# R7FA6E10F register map
Vendor: Renesas Electronics Corporation; Series: RA6; File version: 1.20.00
CPU: CM33 r0p4, little endian, MPU, FPU, VTOR, 4 interrupt priority bits, 96 interrupts
Registers are 8-bit, read-write, reset 0x0 unless marked. A register's access mark holds for its fields unless they carry their own. Offsets are from the block's base; [hi:lo] are bit positions; {n}, {i} and the like mark numbered series; 'fields as' and 'values as' point back to an identical list.

## USBFS — USB 2.0 Full-Speed Module
Base 0x40090000
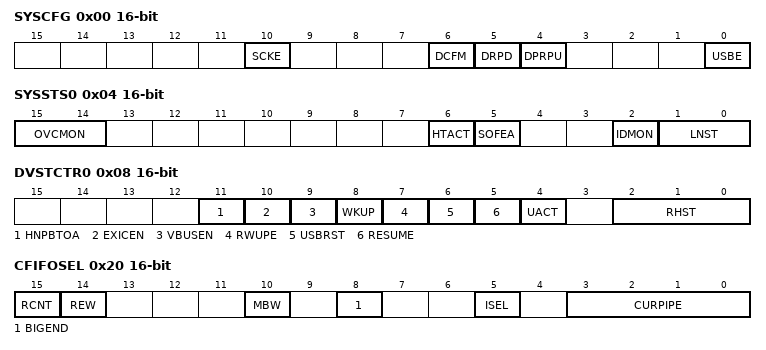
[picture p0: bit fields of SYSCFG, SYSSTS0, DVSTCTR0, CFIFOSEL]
0x00 SYSCFG 16-bit — System Configuration Control Register
  [10] SCKE — USB Clock Enable
    0=Stop clock supply to the USBFS; 1=Enable clock supply to the USBFS
  [6] DCFM — Controller Function Select
    0=Select device controller; 1=Select host controller
  [5] DRPD — D+/D– Line Resistor Control
    0=Disable line pull-down; 1=Enable line pull-down
  [4] DPRPU — D+ Line Resistor Control
    0=Disable line pull-up; 1=Enable line pull-up
  [0] USBE — USBFS Operation Enable
    0=Disable; 1=Enable
0x04 SYSSTS0 16-bit ro (reset mask 0x3FFB) — System Configuration Status Register 0
  [15:14] OVCMON — External USB_OVRCURA/ USB_OVRCURB Input Pin Monitor
  [6] HTACT — USB Host Sequencer Status Monitor
    0=Host sequencer completely stopped; 1=Host sequencer not completely stopped
  [5] SOFEA — Active Monitor When the Host Controller Is Selected
    0=SOF output stopped; 1=SOF output operating
  [2] IDMON — External ID0 Input Pin Monitor
    0=USB_ID pin is low; 1=USB_ID pin is high
  [1:0] LNST — USB Data Line Status Monitor
0x08 DVSTCTR0 16-bit — Device State Control Register 0
  [11] HNPBTOA — Host Negotiation Protocol (HNP) Control
  [10] EXICEN — USB_EXICEN Output Pin Control
    0=Output low on external USB_EXICEN pin; 1=Output high on external USB_EXICEN pin
  [9] VBUSEN — USB_VBUSEN Output Pin Control
    0=Output low on external USB_VBUSEN pin; 1=Output high on external USB_VBUSEN pin
  [8] WKUP — Wakeup Output
    0=Do not output remote wakeup signal; 1=Output remote wakeup signal
  [7] RWUPE — Wakeup Detection Enable
    0=Disable downstream port remote wakeup; 1=Enable downstream port remote wakeup
  [6] USBRST — USB Bus Reset Output
    0=Do not output USB bus reset signal; 1=Output USB bus reset signal
  [5] RESUME — Resume Output
    0=Do not output resume signal; 1=Output resume signal
  [4] UACT — USB Bus Enable
    0=Disable downstream port (disable SOF transmission); 1=Enable downstream port (enable SOF transmission)
  [2:0] RHST ro — USB Bus Reset Status
    0=In host controller mode: Communication speed indeterminate (powered state or no connection) In device controller mode: Communication speed indeterminate; 1=In host controller mode: Low-speed connection In device controller mode: USB bus reset in progress; 2=In host controller mode: Full-speed connection In device controller mode: USB bus reset in progress or full-speed connection; 3=Setting prohibited; other=Others (In host controller mode: USB bus reset in progress In device controller mode: Setting prohibited)
0x14 CFIFO 16-bit — CFIFO Port Register
  [15:0] FIFOPORT
0x14 CFIFOL (alternate view of CFIFO) — CFIFO Port Register
  [7:0] FIFOPORT
{0x18+4i} D{i}FIFO (i=0..1) 16-bit — D{i}FIFO Port Register
  [15:0] FIFOPORT
{0x18+4i} D{i}FIFOL (i=0..1) (alternate view of D{i}FIFO) — D{i}FIFO Port Register
  [7:0] FIFOPORT
0x20 CFIFOSEL 16-bit — CFIFO Port Select Register
  [15] RCNT — Read Count Mode
    0=The DTLN[8:0] bits (CFIFOCTR.DTLN[8:0], D0FIFOCTR.DTLN[8:0], D1FIFOCTR.DTLN[8:0]) are cleared when all receive data is read from the CFIFO. In double buffer mode, the DTLN[8:0] value is cleared when all data is read from only a single plane.; 1=The DTLN[8:0] bits are decremented each time the receive data is read from the CFIFO
  [14] REW wo — Buffer Pointer Rewind
    0=Do not rewind buffer pointer; 1=Rewind buffer pointer
  [10] MBW — CFIFO Port Access Bit Width
    0=8-bit width; 1=16-bit width
  [8] BIGEND — CFIFO Port Endian Control
    0=Little endian; 1=Big endian
  [5] ISEL — CFIFO Port Access Direction When DCP Is Selected
    0=Select reading from the FIFO buffer; 1=Select writing to the FIFO buffer
  [3:0] CURPIPE — CFIFO Port Access Pipe Specification
    0=Default Control Pipe; {v}=Pipe {v} (v=1..9); other=Others (Setting prohibited)
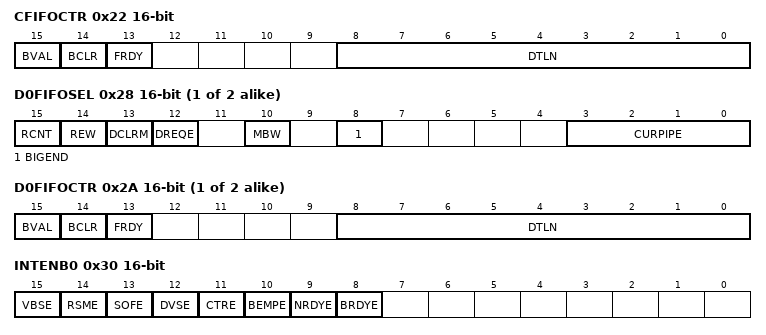
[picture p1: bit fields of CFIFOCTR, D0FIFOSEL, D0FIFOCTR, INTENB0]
0x22 CFIFOCTR 16-bit — CFIFO Port Control Register
  [15] BVAL — Buffer Memory Valid Flag
    0=Invalid (writing 0 has no effect); 1=Writing ended
  [14] BCLR wo — CPU Buffer Clear
    0=No operation; 1=Clear FIFO buffer on the CPU side
  [13] FRDY ro — FIFO Port Ready
    0=FIFO port access disabled; 1=FIFO port access enabled
  [8:0] DTLN ro — Receive Data Length
{0x28+4i} D{i}FIFOSEL (i=0..1) 16-bit — D{i}FIFO Port Select Register
  [15] RCNT — Read Count Mode
    0=Clear DTLN[8:0] bits in (CFIFOCTR.DTLN[8:0], D0FIFOCTR.DTLN[8:0], D1FIFOCTR.DTLN[8:0]) when all receive data is read from DnFIFO (after read of a single plane in double buffer mode); 1=Decrement DTLN[8:0] bits each time receive data is read from DnFIFO
  [14] REW wo — Buffer Pointer Rewind
    0=Do not rewind buffer pointer; 1=Rewind buffer pointer
  [13] DCLRM — Auto Buffer Memory Clear Mode Accessed after Specified Pipe Data is Read
    0=Disable auto buffer clear mode; 1=Enable auto buffer clear mode
  [12] DREQE — DMA/DTC Transfer Request Enable
    0=Disable DMA/DTC transfer request; 1=Enable DMA/DTC transfer request
  [10] MBW — FIFO Port Access Bit Width
    0=8-bit width; 1=16-bit width
  [8] BIGEND — FIFO Port Endian Control
    0=Little endian; 1=Big endian
  [3:0] CURPIPE — FIFO Port Access Pipe Specification
    values as CFIFOSEL.CURPIPE
{0x2A+4i} D{i}FIFOCTR (i=0..1) 16-bit — D{i}FIFO Port Control Register
  [15] BVAL — Buffer Memory Valid Flag
    0=Invalid (writing 0 has no effect); 1=Writing ended
  [14] BCLR — CPU Buffer Clear
    0=No operation; 1=Clear FIFO buffer on the CPU side
  [13] FRDY ro — FIFO Port Ready
    0=FIFO port access disabled; 1=FIFO port access enabled
  [8:0] DTLN ro — Receive Data Length
0x30 INTENB0 16-bit — Interrupt Enable Register 0
  [all] fields
    0=Disable interrupt request; 1=Enable interrupt request
  [15] VBSE — VBUS Interrupt Enable
  [14] RSME — Resume Interrupt Enable
  [13] SOFE — Frame Number Update Interrupt Enable
  [12] DVSE — Device State Transition Interrupt Enable
  [11] CTRE — Control Transfer Stage Transition Interrupt Enable
  [10] BEMPE — Buffer Empty Interrupt Enable
  [9] NRDYE — Buffer Not Ready Response Interrupt Enable
  [8] BRDYE — Buffer Ready Interrupt Enable
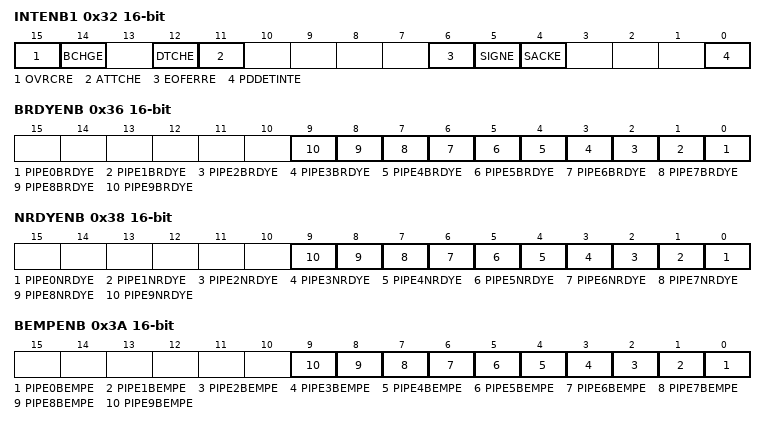
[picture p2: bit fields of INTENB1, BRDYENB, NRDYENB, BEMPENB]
0x32 INTENB1 16-bit — Interrupt Enable Register 1
  [all] fields
    0=Disable interrupt request; 1=Enable interrupt request
  [15] OVRCRE — Overcurrent Input Change Interrupt Enable
  [14] BCHGE — USB Bus Change Interrupt Enable
  [12] DTCHE — Disconnection Detection Interrupt Enable
  [11] ATTCHE — Connection Detection Interrupt Enable
  [6] EOFERRE — EOF Error Detection Interrupt Enable
  [5] SIGNE — Setup Transaction Error Interrupt Enable
  [4] SACKE — Setup Transaction Normal Response Interrupt Enable
  [0] PDDETINTE — PDDETINT Detection Interrupt Request Enable
0x36 BRDYENB 16-bit — BRDY Interrupt Enable Register
  [all] fields
    0=Disable interrupt request; 1=Enable interrupt request
  [n] PIPE{n}BRDYE (n=0..9) — BRDY Interrupt Enable for Pipe {n}
0x38 NRDYENB 16-bit — NRDY Interrupt Enable Register
  [all] fields
    0=Disable interrupt request; 1=Enable interrupt request
  [n] PIPE{n}NRDYE (n=0..9) — NRDY Interrupt Enable for Pipe {n}
0x3A BEMPENB 16-bit — BEMP Interrupt Enable Register
  [all] fields
    0=Disable interrupt request; 1=Enable interrupt request
  [n] PIPE{n}BEMPE (n=0..9) — BEMP Interrupt Enable for Pipe {n}
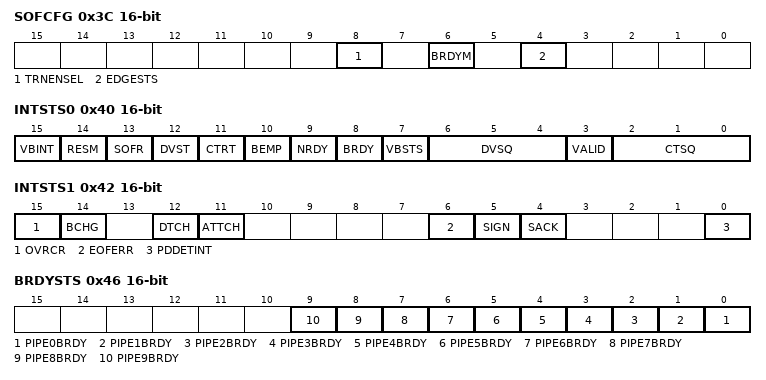
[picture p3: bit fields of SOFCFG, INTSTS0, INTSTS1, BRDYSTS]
0x3C SOFCFG 16-bit — SOF Output Configuration Register
  [8] TRNENSEL — Transaction-Enabled Time Select
    0=Not low-speed communication; 1=Low-speed communication
  [6] BRDYM — BRDY Interrupt Status Clear Timing
    0=Clear BRDY flag by software; 1=Clear BRDY flag by the USBFS through a data read from the FIFO buffer or data write to the FIFO buffer
  [4] EDGESTS ro — Edge Interrupt Output Status Monitor
0x40 INTSTS0 16-bit (reset mask 0xEF6F) — Interrupt Status Register 0
  [15] VBINT — VBUS Interrupt Status
    0=No VBUS interrupt occurred; 1=VBUS interrupt occurred
  [14] RESM — Resume Interrupt Status
    0=No resume interrupt occurred; 1=Resume interrupt occurred
  [13] SOFR — Frame Number Refresh Interrupt Status
    0=No SOF interrupt occurred; 1=SOF interrupt occurred
  [12] DVST — Device State Transition Interrupt Status
    0=No device state transition interrupt occurred; 1=Device state transition interrupt occurred
  [11] CTRT — Control Transfer Stage Transition Interrupt Status
    0=No control transfer stage transition interrupt occurred; 1=Control transfer stage transition interrupt occurred
  [10] BEMP ro — Buffer Empty Interrupt Status
    0=No BEMP interrupt occurred; 1=BEMP interrupt occurred
  [9] NRDY ro — Buffer Not Ready Interrupt Status
    0=No NRDY interrupt occurred; 1=NRDY interrupt occurred
  [8] BRDY ro — Buffer Ready Interrupt Status
    0=No BRDY interrupt occurred; 1=BRDY interrupt occurred
  [7] VBSTS ro — VBUS Input Status
    0=USB_VBUS pin is low; 1=USB_VBUS pin is high
  [6:4] DVSQ ro — Device State
    0=Powered state; 1=Default state; 2=Address state; 3=Configured state; other=Others (Suspend state)
  [3] VALID — USB Request Reception
    0=Setup packet not received; 1=Setup packet received
  [2:0] CTSQ ro — Control Transfer Stage
    0=Idle or setup stage; 1=Control read data stage; 2=Control read status stage; 3=Control write data stage; 4=Control write status stage; 5=Control write (no data) status stage; 6=Control transfer sequence error
0x42 INTSTS1 16-bit — Interrupt Status Register 1
  [15] OVRCR — Overcurrent Input Change Interrupt Status
    0=No OVRCR interrupt occurred; 1=OVRCR interrupt occurred
  [14] BCHG — USB Bus Change Interrupt Status
    0=No BCHG interrupt occurred; 1=BCHG interrupt occurred
  [12] DTCH — USB Disconnection Detection Interrupt Status
    0=No DTCH interrupt occurred; 1=DTCH interrupt occurred
  [11] ATTCH — ATTCH Interrupt Status
    0=No ATTCH interrupt occurred; 1=ATTCH interrupt occurred
  [6] EOFERR — EOF Error Detection Interrupt Status
    0=No EOFERR interrupt occurred; 1=EOFERR interrupt occurred
  [5] SIGN — Setup Transaction Error Interrupt Status
    0=No SIGN interrupt occurred; 1=SIGN interrupt occurred
  [4] SACK — Setup Transaction Normal Response Interrupt Status
    0=No SACK interrupt occurred; 1=SACK interrupt occurred
  [0] PDDETINT — PDDET Detection Interrupt Status Flag
    0=No PDDET interrupt occurred; 1=PDDET interrupt occurred
0x46 BRDYSTS 16-bit — BRDY Interrupt Status Register
  [all] fields
    0=No BRDY interrupt occurred; 1=BRDY interrupt occurred
  [n] PIPE{n}BRDY (n=0..9) — BRDY Interrupt Status for Pipe {n}
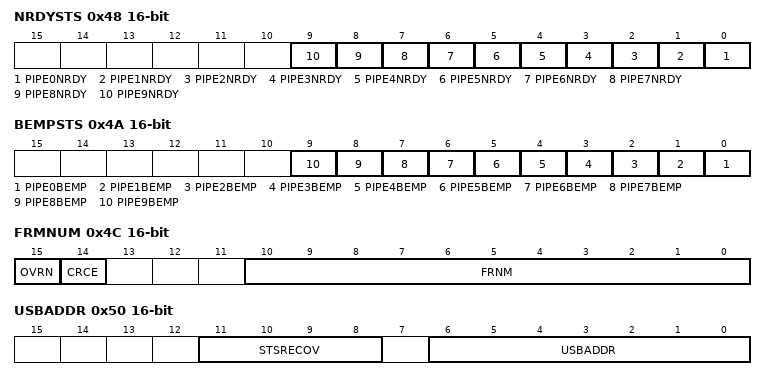
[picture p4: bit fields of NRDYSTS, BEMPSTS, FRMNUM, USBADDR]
0x48 NRDYSTS 16-bit — NRDY Interrupt Status Register
  [all] fields
    0=No NRDY interrupt occurred; 1=NRDY interrupt occurred
  [n] PIPE{n}NRDY (n=0..9) — NRDY Interrupt Status for Pipe {n}
0x4A BEMPSTS 16-bit — BEMP Interrupt Status Register
  [all] fields
    0=No BEMP interrupt occurred; 1=BEMP interrupt occurred
  [n] PIPE{n}BEMP (n=0..9) — BEMP Interrupt Status for Pipe {n}
0x4C FRMNUM 16-bit — Frame Number Register
  [15] OVRN — Overrun/Underrun Detection Status
    0=No error occurred; 1=Error occurred
  [14] CRCE — Receive Data Error
    0=No error occurred; 1=Error occurred
  [10:0] FRNM ro — Frame Number
0x4E DVCHGR 16-bit — Device State Change Register
  [15] DVCHG — Device State Change
    0=Disable writes to the USBADDR.STSRECOV[3:0] and USBADDR.USBADDR[6:0] bits; 1=Enable writes to the USBADDR.STSRECOV[3:0] and USBADDR.USBADDR[6:0] bits
0x50 USBADDR 16-bit — USB Address Register
  [11:8] STSRECOV — Status Recovery
    4=Recovery in device controller mode: Setting prohibited Recovery in host controller mode: Return to the low-speed state (bits DVSTCTR0.RHST[2:0] = 001b); 8=Recovery in device controller mode: Setting prohibited Recovery in host controller mode: Return to the full-speed state (bits DVSTCTR0.RHST[2:0] = 010b); 9=Recovery in device controller mode: Return to the full-speed state (bits DVSTCTR0.RHST[2:0] = 010b), bits INTSTS0.DVSQ[2:0] = 001b (default state) Recovery in host controller mode: Setting prohibited; 10=Recovery in device controller mode: Return to the full-speed state (bits DVSTCTR0.RHST[2:0] = 010b), bits INTSTS0.DVSQ[2:0] = 010b (address state) Recovery in host controller mode: Setting prohibited; 11=Recovery in device controller mode: Return to the full-speed state (bits DVSTCTR0.RHST[2:0] = 010b), bits INTSTS0.DVSQ[2:0] = 011b (configured state) Recovery in host controller mode: Setting prohibited; other=Others (Setting prohibited)
  [6:0] USBADDR — USB Address
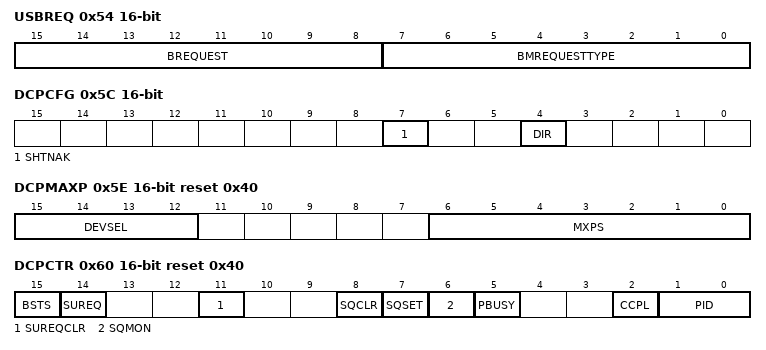
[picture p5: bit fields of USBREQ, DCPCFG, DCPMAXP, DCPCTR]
0x54 USBREQ 16-bit — USB Request Type Register
  [15:8] BREQUEST — Request
  [7:0] BMREQUESTTYPE — Request Type
0x56 USBVAL 16-bit — USB Request Value Register
  [15:0] WVALUE — Value
0x58 USBINDX 16-bit — USB Request Index Register
  [15:0] WINDEX — Index
0x5A USBLENG 16-bit — USB Request Length Register
  [15:0] WLENTUH — Length
0x5C DCPCFG 16-bit — DCP Configuration Register
  [7] SHTNAK — Pipe Disabled at End of Transfer
    0=Keep pipe open after transfer ends; 1=Disable pipe after transfer ends
  [4] DIR — Transfer Direction
    0=Data receiving direction; 1=Data transmitting direction
0x5E DCPMAXP 16-bit reset 0x40 — DCP Maximum Packet Size Register
  [15:12] DEVSEL — Device Select
    0=Address 0000b; 1=Address 0001b; 2=Address 0010b; 3=Address 0011b; 4=Address 0100b; 5=Address 0101b; other=Others (Setting prohibited)
  [6:0] MXPS — Maximum Packet Size
0x60 DCPCTR 16-bit reset 0x40 — DCP Control Register
  [15] BSTS ro — Buffer Status
    0=Buffer access disabled; 1=Buffer access enabled
  [14] SUREQ — Setup Token Transmission
    0=Invalid (writing 0 has no effect); 1=Transmit setup packet
  [11] SUREQCLR — SUREQ Bit Clear
    0=Invalid (writing 0 has no effect); 1=Clear SUREQ to 0
  [8] SQCLR — Sequence Toggle Bit Clear
    0=Invalid (writing 0 has no effect); 1=Clear the expected value for the next transaction to DATA0
  [7] SQSET — Sequence Toggle Bit Set
    0=Invalid (writing 0 has no effect); 1=Set the expected value for the next transaction to DATA1
  [6] SQMON ro — Sequence Toggle Bit Monitor
    0=DATA0; 1=ATA1
  [5] PBUSY ro — Pipe Busy
    0=DCP not used for the USB bus; 1=DCP in use for the USB bus
  [2] CCPL — Control Transfer End Enable
    0=Disable control transfer completion; 1=Enable control transfer completion
  [1:0] PID — Response PID
    0=NAK response; 1=BUF response (depends on the buffer state); 2=STALL response; 3=STALL response
0x64 PIPESEL 16-bit — Pipe Window Select Register
  [3:0] PIPESEL — Pipe Window Select
    0=No pipe selected; {v}=Pipe {v} (v=1..9); other=Others (Setting prohibited)
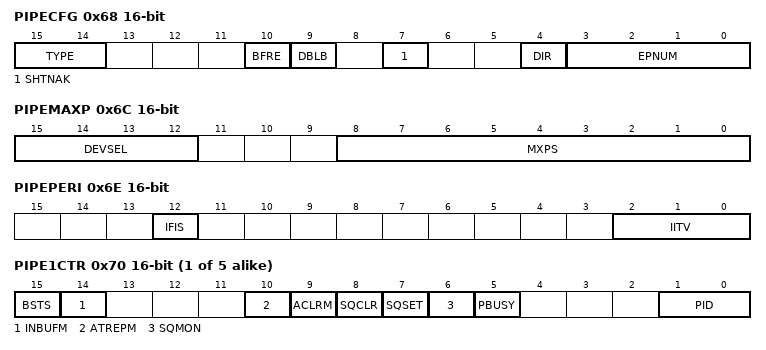
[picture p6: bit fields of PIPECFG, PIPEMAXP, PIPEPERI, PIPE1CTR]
0x68 PIPECFG 16-bit — Pipe Configuration Register
  [15:14] TYPE — Transfer Type
    0=Pipe not used; 1=Pipes 1 and 2: Bulk transfer Pipes 3 to 5: Bulk transfer Pipes 6 to 9: Setting prohibited; 2=Pipes 1 and 2: Setting prohibited Pipes 3 to 5: Setting prohibited Pipes 6 to 9: Interrupt transfer; 3=Pipes 1 and 2: Isochronous transfer Pipes 3 to 5: Setting prohibited Pipes 6 to 9: Setting prohibited
  [10] BFRE — BRDY Interrupt Operation Specification
    0=Generate BRDY interrupt on transmitting or receiving data; 1=Generate BRDY interrupt on completion of reading data
  [9] DBLB — Double Buffer Mode
    0=Single buffer; 1=Double buffer
  [7] SHTNAK — Pipe Disabled at End of Transfer
    0=Continue pipe operation after transfer ends; 1=Disable pipe after transfer ends
  [4] DIR — Transfer Direction
    0=Receiving direction; 1=Transmitting direction
  [3:0] EPNUM — Endpoint Number
0x6C PIPEMAXP 16-bit (reset mask 0xFFBF) — Pipe Maximum Packet Size Register
  [15:12] DEVSEL — Device Select
    values as DCPMAXP.DEVSEL
  [8:0] MXPS — Maximum Packet Size
0x6E PIPEPERI 16-bit — Pipe Cycle Control Register
  [12] IFIS — Isochronous IN Buffer Flush
    0=Do not flush buffer; 1=Flush buffer
  [2:0] IITV — Interval Error Detection Interval
{0x6E+2i} PIPE{i}CTR (i=1..5) 16-bit — PIPE{i} Control Registers
  [15] BSTS ro — Buffer Status
    0=Buffer access by the CPU disabled; 1=Buffer access by the CPU enabled
  [14] INBUFM ro — Transmit Buffer Monitor
    0=No data to be transmitted is in the FIFO buffer; 1=Data to be transmitted is in the FIFO buffer
  [10] ATREPM — Auto Response Mode
    0=Disable auto response mode; 1=Enable auto response mode
  [9] ACLRM — Auto Buffer Clear Mode
    0=Disable; 1=Enable (initialize all buffers)
  [8] SQCLR — Sequence Toggle Bit Clear
    values as DCPCTR.SQCLR
  [7] SQSET — Sequence Toggle Bit Set
    values as DCPCTR.SQSET
  [6] SQMON ro — Sequence Toggle Bit Confirmation
    0=DATA0; 1=DATA1
  [5] PBUSY ro — Pipe Busy
    0=Pipe n not in use for the transaction; 1=Pipe n in use for the transaction
  [1:0] PID — Response PID
    0=NAK response; 1=BUF response (depends buffer state); 2=STALL response; 3=STALL response
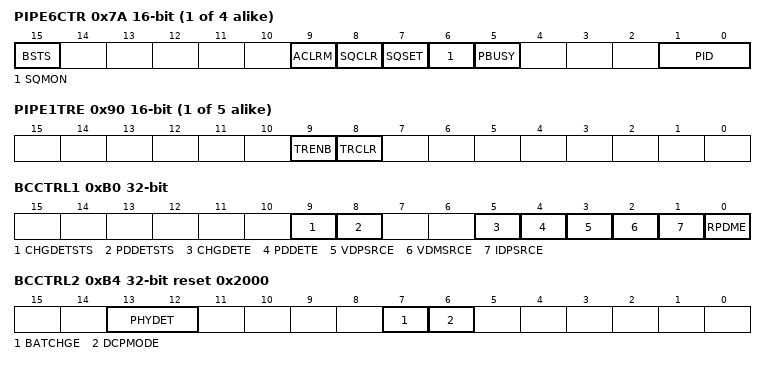
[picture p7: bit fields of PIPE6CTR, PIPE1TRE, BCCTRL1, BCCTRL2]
{0x6E+2i} PIPE{i}CTR (i=6..9) 16-bit — PIPE{i} Control Registers
  [15] BSTS ro — Buffer Status
    0=Buffer access disabled; 1=Buffer access enabled
  [9] ACLRM — Auto Buffer Clear Mode
    0=Disable; 1=Enable (all buffers initialized)
  [8] SQCLR wo — Sequence Toggle Bit Clear
    values as DCPCTR.SQCLR
  [7] SQSET wo — Sequence Toggle Bit Set
    0=Invalid (writing 0 has no effect); 1=Set the expected value for the next transaction to DATA0
  [6] SQMON ro — Sequence Toggle Bit Confirmation
    0=DATA0; 1=DATA1
  [5] PBUSY ro — Pipe Busy
    values as PIPE1CTR.PBUSY
  [1:0] PID — Response PID
    values as PIPE1CTR.PID
{0x8C+4i} PIPE{i}TRE (i=1..5) 16-bit — PIPE{i} Transaction Counter Enable Register
  [9] TRENB — Transaction Counter Enable
    0=Disable transaction counter; 1=Enable transaction counter
  [8] TRCLR — Transaction Counter Clear
    0=Invalid (writing 0 has no effect); 1=Clear counter value
{0x8E+4i} PIPE{i}TRN (i=1..5) 16-bit — PIPE{i} Transaction Counter Register
  [15:0] TRNCNT — Transaction Counter
0xB0 BCCTRL1 32-bit — Battery Charging Control Register 1
  [9] CHGDETSTS ro — D- Line 0.6 V Input Detection Status Flag
    0=Not detected; 1=Detected
  [8] PDDETSTS ro — D+ Line 0.6 V Input Detection Status Flag
    0=Not detected; 1=Detected
  [5] CHGDETE — D- Line 0.6 V Input Detection Control
    0=Disable detection; 1=Enable detection
  [4] PDDETE — D+ Line 0.6 V Input Detection Control
    0=Disable detection; 1=Enable detection
  [3] VDPSRCE — D+ Line VDPSRC (0.6 V) Output Control
    0=Stopped; 1=0.6 V output
  [2] VDMSRCE — D- Line VDMSRC (0.6 V) Output Control
    0=Stopped; 1=0.6 V output
  [1] IDPSRCE — D+ Line IDPSRC Output Control
    0=Stopped; 1=10 µA output
  [0] RPDME — D- Line Pull-down Control
    0=Disable D- Line Pull-down; 1=Enable D- Line Pull-down
0xB4 BCCTRL2 32-bit reset 0x2000 — Battery Charging Control Register 2
  [13:12] PHYDET — Detect Sensitivity Adjustment
  [7] BATCHGE — Battery Charging Enable
    0=Disable Battery Charging; 1=Enable Battery Charging
  [6] DCPMODE — Dedicated Charging Port (DCP) Mode Control
    0=Disable DCP; 1=Enable DCP
{0xD0+2i} DEVADD{i} (i=0..5) 16-bit — Device Address {i} Configuration Register
  [7:6] USBSPD — Transfer Speed of Communication Target Device
    0=Do not use DEVADDn; 1=Low-speed; 2=Full-speed; 3=Setting prohibited
0xF4 PHYSECTRL 32-bit — PHY Single-ended Receiver Control Register
  [4] CNEN — Single-ended Receiver Enable
    0=Single-ended receiver operation is disabled; 1=Single-ended receiver operation is enabled
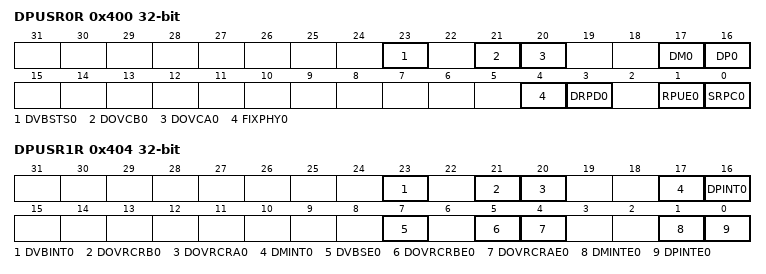
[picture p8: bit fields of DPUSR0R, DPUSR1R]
0x400 DPUSR0R 32-bit (reset mask 0xFF4CFFFF) — Deep Software Standby USB Transceiver Control/Pin Monitor Register
  [23] DVBSTS0 ro — USB VBUS Input
  [21] DOVCB0 ro — USB OVRCURB Input
  [20] DOVCA0 ro — USB OVRCURA Input
  [17] DM0 ro — USB D- Input
  [16] DP0 ro — USB D+ Input
  [4] FIXPHY0 — USB Transceiver Output Fix
    0=Fix outputs in Normal mode and on return from Deep Software Standby mode; 1=Fix outputs on transition to Deep Software Standby mode
  [3] DRPD0 — D+/D- Pull-Down Resistor Control
    0=Disable DP/DM pull-down resistor; 1=Enable DP/DM pull-down resistor
  [1] RPUE0 — DP Pull-Up Resistor Control
    0=Disable DP pull-up resistor; 1=Enable DP pull-up resistor
  [0] SRPC0 — USB Single-ended Receiver Control
    0=Disable input through DP and DM inputs; 1=Enable input through DP and DM inputs
0x404 DPUSR1R 32-bit — Deep Software Standby USB Suspend/Resume Interrupt Register
  [23] DVBINT0 ro — USB VBUS Interrupt Source Recovery
    0=System has not recovered from Deep Software Standby mode; 1=System recovered from Deep Software Standby mode because of VBUS input
  [21] DOVRCRB0 ro — USB OVRCURB Interrupt Source Recovery
    0=System has not recovered from Deep Software Standby mode; 1=System recovered from Deep Software Standby mode because of OVRCURB input
  [20] DOVRCRA0 ro — USB OVRCURA Interrupt Source Recovery
    0=System has not recovered from Deep Software Standby mode; 1=System recovered from Deep Software Standby mode because of OVRCURA input
  [17] DMINT0 ro — USB DM Interrupt Source Recovery
    0=System has not recovered from Deep Software Standby mode; 1=System recovered from Deep Software Standby mode because of DM input
  [16] DPINT0 ro — USB DP Interrupt Source Recovery
    0=System has not recovered from Deep Software Standby mode; 1=System recovered from Deep Software Standby mode because of DP
  [7] DVBSE0 — USB VBUS Interrupt Enable/Clear
    0=Disable recovery from Deep Software Standby mode by VBUS input; 1=Enable recovery from Deep Software Standby mode by VBUS input
  [5] DOVRCRBE0 — USB OVRCURB Interrupt Enable/Clear
    0=Disable recovery from Deep Software Standby mode by OVRCURB input; 1=Enable recovery from Deep Software Standby mode by OVRCURB input
  [4] DOVRCRAE0 — USB OVRCURA Interrupt Enable/Clear
    0=Disable recovery from Deep Software Standby mode by OVRCURA input; 1=Enable recovery from Deep Software Standby mode by OVRCURA input
  [1] DMINTE0 — USB DM Interrupt Enable/Clear
    0=Disable recovery from Deep Software Standby mode by DM input; 1=Enable recovery from Deep Software Standby mode by DM input
  [0] DPINTE0 — USB DP Interrupt Enable/Clear
    0=Disable recovery from Deep Software Standby mode by DP input; 1=Enable recovery from Deep Software Standby mode by DP input
